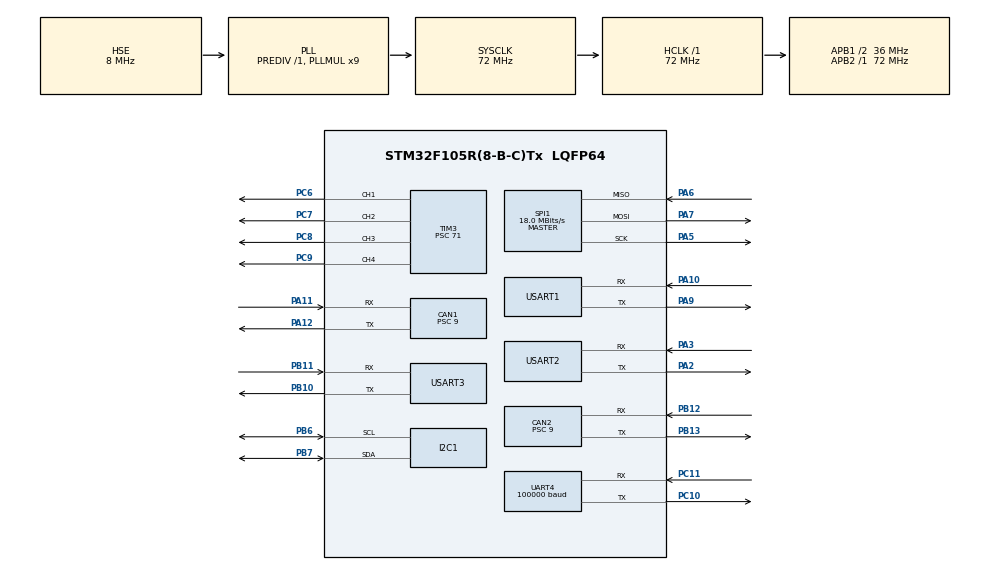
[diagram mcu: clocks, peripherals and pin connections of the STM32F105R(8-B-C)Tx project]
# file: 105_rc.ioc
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CAN1.BS1=CAN_BS1_2TQ
CAN1.CalculateBaudRate=1000000
CAN1.CalculateTimeBit=1000
CAN1.CalculateTimeQuantum=250.0
CAN1.Prescaler=9
CAN2.BS1=CAN_BS1_2TQ
CAN2.CalculateBaudRate=1000000
CAN2.CalculateTimeBit=1000
CAN2.CalculateTimeQuantum=250.0
CAN2.Prescaler=9
Dma.Request0=UART4_RX
Dma.Request1=USART1_RX
Dma.Request2=USART1_TX
Dma.Request3=USART2_RX
Dma.Request4=USART2_TX
Dma.Request5=USART3_RX
Dma.Request6=USART3_TX
Dma.UART4_RX.0.Direction=DMA_PERIPH_TO_MEMORY
Dma.UART4_RX.0.Instance=DMA2_Channel3
Dma.UART4_RX.0.MemDataAlignment=DMA_MDATAALIGN_BYTE
Dma.UART4_RX.0.MemInc=DMA_MINC_ENABLE
Dma.UART4_RX.0.Mode=DMA_NORMAL
Dma.UART4_RX.0.PeriphDataAlignment=DMA_PDATAALIGN_BYTE
Dma.UART4_RX.0.PeriphInc=DMA_PINC_DISABLE
Dma.UART4_RX.0.Priority=DMA_PRIORITY_LOW
Dma.USART1_RX.1.Direction=DMA_PERIPH_TO_MEMORY
Dma.USART1_RX.1.Instance=DMA1_Channel5
Dma.USART1_RX.1.MemDataAlignment=DMA_MDATAALIGN_BYTE
Dma.USART1_RX.1.MemInc=DMA_MINC_ENABLE
Dma.USART1_RX.1.Mode=DMA_NORMAL
Dma.USART1_RX.1.PeriphDataAlignment=DMA_PDATAALIGN_BYTE
Dma.USART1_RX.1.PeriphInc=DMA_PINC_DISABLE
Dma.USART1_RX.1.Priority=DMA_PRIORITY_LOW
Dma.USART1_TX.2.Direction=DMA_MEMORY_TO_PERIPH
Dma.USART1_TX.2.Instance=DMA1_Channel4
Dma.USART1_TX.2.MemDataAlignment=DMA_MDATAALIGN_BYTE
Dma.USART1_TX.2.MemInc=DMA_MINC_ENABLE
Dma.USART1_TX.2.Mode=DMA_NORMAL
Dma.USART1_TX.2.PeriphDataAlignment=DMA_PDATAALIGN_BYTE
Dma.USART1_TX.2.PeriphInc=DMA_PINC_DISABLE
Dma.USART1_TX.2.Priority=DMA_PRIORITY_LOW
Dma.USART2_RX.3.Direction=DMA_PERIPH_TO_MEMORY
Dma.USART2_RX.3.Instance=DMA1_Channel6
Dma.USART2_RX.3.MemDataAlignment=DMA_MDATAALIGN_BYTE
Dma.USART2_RX.3.MemInc=DMA_MINC_ENABLE
Dma.USART2_RX.3.Mode=DMA_NORMAL
Dma.USART2_RX.3.PeriphDataAlignment=DMA_PDATAALIGN_BYTE
Dma.USART2_RX.3.PeriphInc=DMA_PINC_DISABLE
Dma.USART2_RX.3.Priority=DMA_PRIORITY_LOW
Dma.USART2_TX.4.Direction=DMA_MEMORY_TO_PERIPH
Dma.USART2_TX.4.Instance=DMA1_Channel7
Dma.USART2_TX.4.MemDataAlignment=DMA_MDATAALIGN_BYTE
Dma.USART2_TX.4.MemInc=DMA_MINC_ENABLE
Dma.USART2_TX.4.Mode=DMA_NORMAL
Dma.USART2_TX.4.PeriphDataAlignment=DMA_PDATAALIGN_BYTE
Dma.USART2_TX.4.PeriphInc=DMA_PINC_DISABLE
Dma.USART2_TX.4.Priority=DMA_PRIORITY_LOW
Dma.USART3_RX.5.Direction=DMA_PERIPH_TO_MEMORY
Dma.USART3_RX.5.Instance=DMA1_Channel3
Dma.USART3_RX.5.MemDataAlignment=DMA_MDATAALIGN_BYTE
Dma.USART3_RX.5.MemInc=DMA_MINC_ENABLE
Dma.USART3_RX.5.Mode=DMA_NORMAL
Dma.USART3_RX.5.PeriphDataAlignment=DMA_PDATAALIGN_BYTE
Dma.USART3_RX.5.PeriphInc=DMA_PINC_DISABLE
Dma.USART3_RX.5.Priority=DMA_PRIORITY_LOW
Dma.USART3_TX.6.Direction=DMA_MEMORY_TO_PERIPH
Dma.USART3_TX.6.Instance=DMA1_Channel2
Dma.USART3_TX.6.MemDataAlignment=DMA_MDATAALIGN_BYTE
Dma.USART3_TX.6.MemInc=DMA_MINC_ENABLE
Dma.USART3_TX.6.Mode=DMA_NORMAL
Dma.USART3_TX.6.PeriphDataAlignment=DMA_PDATAALIGN_BYTE
Dma.USART3_TX.6.PeriphInc=DMA_PINC_DISABLE
Dma.USART3_TX.6.Priority=DMA_PRIORITY_LOW
I2C1.I2C_Mode=I2C_Fast
Mcu.Family=STM32F1
Mcu.Name=STM32F105R(8-B-C)Tx
Mcu.Package=LQFP64
NVIC.CAN1_RX0_IRQn=true\:0\:0\:false\:false\:true\:true\:true\:true
NVIC.CAN1_RX1_IRQn=true\:0\:0\:false\:false\:true\:true\:true\:true
NVIC.CAN1_SCE_IRQn=true\:0\:0\:false\:false\:true\:true\:true\:true
NVIC.CAN1_TX_IRQn=true\:0\:0\:false\:false\:true\:true\:true\:true
NVIC.CAN2_RX0_IRQn=true\:0\:0\:false\:false\:true\:true\:true\:true
NVIC.CAN2_RX1_IRQn=true\:0\:0\:false\:false\:true\:true\:true\:true
NVIC.CAN2_SCE_IRQn=true\:0\:0\:false\:false\:true\:true\:true\:true
NVIC.CAN2_TX_IRQn=true\:0\:0\:false\:false\:true\:true\:true\:true
NVIC.DMA1_Channel2_IRQn=true\:0\:0\:false\:false\:true\:false\:true\:true
NVIC.DMA1_Channel3_IRQn=true\:0\:0\:false\:false\:true\:false\:true\:true
NVIC.DMA1_Channel4_IRQn=true\:0\:0\:false\:false\:true\:false\:true\:true
NVIC.DMA1_Channel5_IRQn=true\:0\:0\:false\:false\:true\:false\:true\:true
NVIC.DMA1_Channel6_IRQn=true\:0\:0\:false\:false\:true\:false\:true\:true
NVIC.DMA1_Channel7_IRQn=true\:0\:0\:false\:false\:true\:false\:true\:true
NVIC.DMA2_Channel3_IRQn=true\:0\:0\:false\:false\:true\:false\:true\:true
NVIC.PriorityGroup=NVIC_PRIORITYGROUP_4
NVIC.TIM1_UP_IRQn=true\:15\:0\:false\:false\:true\:false\:true\:true
NVIC.TimeBase=TIM1_UP_IRQn
NVIC.TimeBaseIP=TIM1
NVIC.UART4_IRQn=true\:0\:0\:false\:false\:true\:true\:true\:true
NVIC.USART1_IRQn=true\:0\:0\:false\:false\:true\:true\:true\:true
NVIC.USART2_IRQn=true\:0\:0\:false\:false\:true\:false\:true\:true
NVIC.USART3_IRQn=true\:0\:0\:false\:false\:true\:false\:true\:true
PA10.Mode=Asynchronous
PA10.Signal=USART1_RX
PA11.Mode=CAN_Activate
PA11.Signal=CAN1_RX
PA12.Mode=CAN_Activate
PA12.Signal=CAN1_TX
PA13.Mode=Serial_Wire
PA13.Signal=SYS_JTMS-SWDIO
PA14.Mode=Serial_Wire
PA14.Signal=SYS_JTCK-SWCLK
PA2.Mode=Asynchronous
PA2.Signal=USART2_TX
PA3.Mode=Asynchronous
PA3.Signal=USART2_RX
PA5.Mode=Full_Duplex_Master
PA5.Signal=SPI1_SCK
PA6.Mode=Full_Duplex_Master
PA6.Signal=SPI1_MISO
PA7.Mode=Full_Duplex_Master
PA7.Signal=SPI1_MOSI
PA9.Mode=Asynchronous
PA9.Signal=USART1_TX
PB10.Mode=Asynchronous
PB10.Signal=USART3_TX
PB11.Mode=Asynchronous
PB11.Signal=USART3_RX
PB12.Mode=CAN_Activate
PB12.Signal=CAN2_RX
PB13.Mode=CAN_Activate
PB13.Signal=CAN2_TX
PB6.Mode=I2C
PB6.Signal=I2C1_SCL
PB7.Mode=I2C
PB7.Signal=I2C1_SDA
PC10.Mode=Asynchronous
PC10.Signal=UART4_TX
PC11.Mode=Asynchronous
PC11.Signal=UART4_RX
PC6.Signal=S_TIM3_CH1
PC7.Signal=S_TIM3_CH2
PC8.Signal=S_TIM3_CH3
PC9.Signal=S_TIM3_CH4
PD0-OSC_IN.Mode=HSE-External-Oscillator
PD0-OSC_IN.Signal=RCC_OSC_IN
PD1-OSC_OUT.Mode=HSE-External-Oscillator
PD1-OSC_OUT.Signal=RCC_OSC_OUT
ProjectManager.HeapSize=0x200
ProjectManager.StackSize=0x400
ProjectManager.TargetToolchain=CMake
RCC.AHBFreq_Value=72000000
RCC.APB1CLKDivider=RCC_HCLK_DIV2
RCC.APB1Freq_Value=36000000
RCC.APB1TimFreq_Value=72000000
RCC.APB2Freq_Value=72000000
RCC.APB2TimFreq_Value=72000000
RCC.HCLKFreq_Value=72000000
RCC.PLLMUL=RCC_PLL_MUL9
RCC.PLLSourceVirtual=RCC_PLLSOURCE_HSE
RCC.SYSCLKFreq_VALUE=72000000
RCC.SYSCLKSource=RCC_SYSCLKSOURCE_PLLCLK
RCC.USBFreq_Value=48000000
SH.S_TIM3_CH1.0=TIM3_CH1,PWM Generation1 CH1
SH.S_TIM3_CH2.0=TIM3_CH2,PWM Generation2 CH2
SH.S_TIM3_CH3.0=TIM3_CH3,PWM Generation3 CH3
SH.S_TIM3_CH4.0=TIM3_CH4,PWM Generation4 CH4
SPI1.BaudRatePrescaler=SPI_BAUDRATEPRESCALER_4
SPI1.CalculateBaudRate=18.0 MBits/s
SPI1.Direction=SPI_DIRECTION_2LINES
SPI1.Mode=SPI_MODE_MASTER
SPI1.VirtualType=VM_MASTER
TIM3.Channel-PWM\ Generation1\ CH1=TIM_CHANNEL_1
TIM3.Channel-PWM\ Generation2\ CH2=TIM_CHANNEL_2
TIM3.Channel-PWM\ Generation3\ CH3=TIM_CHANNEL_3
TIM3.Channel-PWM\ Generation4\ CH4=TIM_CHANNEL_4
TIM3.Prescaler=71
UART4.BaudRate=100000
UART4.Parity=PARITY_EVEN
UART4.VirtualMode=Asynchronous
UART4.WordLength=WORDLENGTH_9B
USART1.VirtualMode=VM_ASYNC
USART2.VirtualMode=VM_ASYNC
USART3.VirtualMode=VM_ASYNC
VP_IWDG_VS_IWDG.Mode=IWDG_Activate
VP_SYS_VS_tim1.Mode=TIM1
VP_TIM3_VS_ClockSourceINT.Mode=Internal
board=custom

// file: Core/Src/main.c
/* USER CODE BEGIN Header */
/**
  ******************************************************************************
  * @file           : main.c
  * @brief          : Main program body
  ******************************************************************************
  * @attention
  *
  * Copyright (c) 2026 STMicroelectronics.
  * All rights reserved.
  *
  * This software is licensed under terms that can be found in the LICENSE file
  * in the root directory of this software component.
  * If no LICENSE file comes with this software, it is provided AS-IS.
  *
  ******************************************************************************
  */
/* USER CODE END Header */
#include "main.h"
#include "can.h"
#include "dma.h"
#include "i2c.h"
#include "iwdg.h"
#include "spi.h"
#include "tim.h"
#include "usart.h"
#include "gpio.h"

/* USER CODE BEGIN Includes */
#include "tx_api.h"
#include "robot_init.h"

/* USER CODE END Includes */

void SystemClock_Config(void);

int main(void)
{

  /* MCU Configuration--------------------------------------------------------*/

  /* Reset of all peripherals, Initializes the Flash interface and the Systick. */
  HAL_Init();

  /* Configure the system clock */
  SystemClock_Config();

  /* Initialize all configured peripherals */
  MX_GPIO_Init();
  MX_DMA_Init();
  MX_CAN1_Init();
  MX_CAN2_Init();
  MX_I2C1_Init();
  //MX_IWDG_Init();
  MX_SPI1_Init();
  MX_TIM3_Init();
  MX_UART4_Init();
  MX_USART1_UART_Init();
  MX_USART2_UART_Init();
  MX_USART3_UART_Init();
  /* USER CODE BEGIN 2 */

  /* Start ThreadX */
  tx_kernel_enter();

  /* USER CODE END 2 */

  /* Infinite loop */
  while (1)
  {

  }
}

void SystemClock_Config(void)
{
  RCC_OscInitTypeDef RCC_OscInitStruct = {0};
  RCC_ClkInitTypeDef RCC_ClkInitStruct = {0};

  /** Initializes the RCC Oscillators according to the specified parameters
  * in the RCC_OscInitTypeDef structure.
  */
  RCC_OscInitStruct.OscillatorType = RCC_OSCILLATORTYPE_LSI|RCC_OSCILLATORTYPE_HSE;
  RCC_OscInitStruct.HSEState = RCC_HSE_ON;
  RCC_OscInitStruct.HSEPredivValue = RCC_HSE_PREDIV_DIV1;
  RCC_OscInitStruct.HSIState = RCC_HSI_ON;
  RCC_OscInitStruct.LSIState = RCC_LSI_ON;
  RCC_OscInitStruct.Prediv1Source = RCC_PREDIV1_SOURCE_HSE;
  RCC_OscInitStruct.PLL.PLLState = RCC_PLL_ON;
  RCC_OscInitStruct.PLL.PLLSource = RCC_PLLSOURCE_HSE;
  RCC_OscInitStruct.PLL.PLLMUL = RCC_PLL_MUL9;
  RCC_OscInitStruct.PLL2.PLL2State = RCC_PLL_NONE;
  if (HAL_RCC_OscConfig(&RCC_OscInitStruct) != HAL_OK)
  {
    Error_Handler();
  }

  /** Initializes the CPU, AHB and APB buses clocks
  */
  RCC_ClkInitStruct.ClockType = RCC_CLOCKTYPE_HCLK|RCC_CLOCKTYPE_SYSCLK
                              |RCC_CLOCKTYPE_PCLK1|RCC_CLOCKTYPE_PCLK2;
  RCC_ClkInitStruct.SYSCLKSource = RCC_SYSCLKSOURCE_PLLCLK;
  RCC_ClkInitStruct.AHBCLKDivider = RCC_SYSCLK_DIV1;
  RCC_ClkInitStruct.APB1CLKDivider = RCC_HCLK_DIV2;
  RCC_ClkInitStruct.APB2CLKDivider = RCC_HCLK_DIV1;

  if (HAL_RCC_ClockConfig(&RCC_ClkInitStruct, FLASH_LATENCY_2) != HAL_OK)
  {
    Error_Handler();
  }

  /** Configure the Systick interrupt time
  */
  __HAL_RCC_PLLI2S_ENABLE();
}

/* USER CODE BEGIN 4 */

void tx_application_define(void *first_unused_memory)
{
    Robot_Init();
}

/* USER CODE END 4 */

void HAL_TIM_PeriodElapsedCallback(TIM_HandleTypeDef *htim)
{
  if (htim->Instance == TIM1)
  {
    HAL_IncTick();
  }
}

void Error_Handler(void)
{
  __disable_irq();
  while (1)
  {
  }
}
